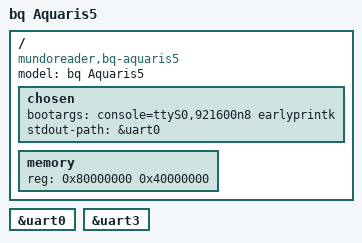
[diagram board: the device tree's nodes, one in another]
/dts-v1/;
#include "mt6589.dtsi"
/ {
	model = "bq Aquaris5";
	compatible = "mundoreader,bq-aquaris5", "mediatek,mt6589";
	chosen {
		bootargs = "console=ttyS0,921600n8 earlyprintk";
		stdout-path = &uart0;
	};
	memory {
		device_type = "memory";
		reg = <0x80000000 0x40000000>;
	};
};
&uart0 {
	status = "okay";
};
&uart3 {
	status = "okay";
};
